AUTOSAR XML (schema 4-0-3)
package /ComponentTypes
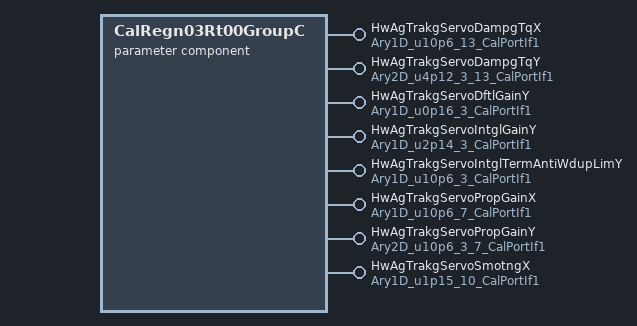
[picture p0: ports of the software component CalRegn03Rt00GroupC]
  parameter sw component type CalRegn03Rt00GroupC
    8 x provide port:
      HwAgTrakgServoDampgTqX: parameter-provide-com-spec{init-value=[0, 3200, 6400, 10724, 11260, 12064, 12868, 13940, 14744, 16620, 21448, 24128, 26808], parameter=Ary1D}, provided-interface=Ary1D_u10p6_13_CalPortIf1
      HwAgTrakgServoDampgTqY: parameter-provide-com-spec{init-value=[[0, 1434, 2867, 4804, 5097, 5593, 6175, 6961, 7595, 8982, 12135, 13677, 15082], [0, 1434, 2867, 4804, 5097, 5593, 6175, 6961, 7595, 8982, 12135, 13677, 15082], [0, 1434, 2867, 4804, 5097, 5593, 6175, 6961, 7595, 8982, 12135, 13677, 15082]], parameter=Ary2D}, provided-interface=Ary2D_u4p12_3_13_CalPortIf1
      HwAgTrakgServoDftlGainY: parameter-provide-com-spec{init-value=[393, 393, 393], parameter=Ary1D}, provided-interface=Ary1D_u0p16_3_CalPortIf1
      HwAgTrakgServoIntglGainY: parameter-provide-com-spec{init-value=[4915, 4915, 4915], parameter=Ary1D}, provided-interface=Ary1D_u2p14_3_CalPortIf1
      HwAgTrakgServoIntglTermAntiWdupLimY: parameter-provide-com-spec{init-value=[128, 96, 64], parameter=Ary1D}, provided-interface=Ary1D_u10p6_3_CalPortIf1
      HwAgTrakgServoPropGainX: parameter-provide-com-spec{init-value=[0, 128, 256, 512, 1280, 1600, 1920], parameter=Ary1D}, provided-interface=Ary1D_u10p6_7_CalPortIf1
      HwAgTrakgServoPropGainY: parameter-provide-com-spec{init-value=[[0, 6, 16, 47, 179, 205, 208], [0, 6, 16, 47, 179, 205, 208], [0, 6, 16, 47, 179, 205, 208]], parameter=Ary2D}, provided-interface=Ary2D_u10p6_3_7_CalPortIf1
      HwAgTrakgServoSmotngX: parameter-provide-com-spec{init-value=[0, 3277, 6554, 9830, 13107, 19661, 22938, 26214, 29491, 32768], parameter=Ary1D}, provided-interface=Ary1D_u1p15_10_CalPortIf1
